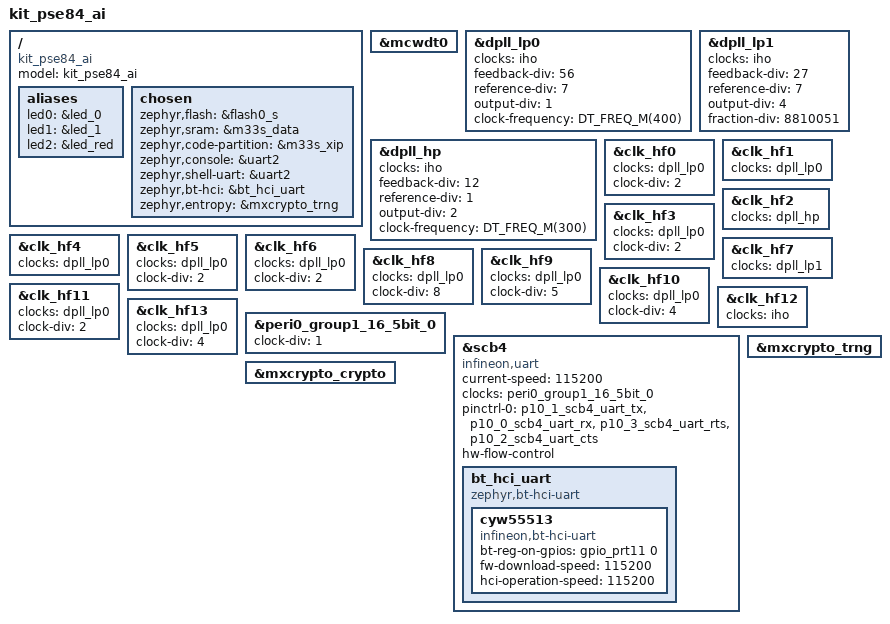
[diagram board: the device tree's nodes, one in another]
/*
 * SPDX-FileCopyrightText: Copyright (c) 2026 Infineon Technologies AG,
 * SPDX-FileCopyrightText: or an affiliate of Infineon Technologies AG. All rights reserved.
 *
 * SPDX-License-Identifier: Apache-2.0
 */

/dts-v1/;
#include <infineon/edge/mpns/pse846gps2dbzc4a_s.dtsi>
#include <infineon/edge/pse84/pse84.cm33.dtsi>
#include <infineon/edge/pse84/system_clocks.dtsi>

#include "kit_pse84_ai_common.dtsi"
#include "kit_pse84_ai_memory_map.dtsi"

/ {
	compatible = "kit_pse84_ai";
	model = "kit_pse84_ai";

	aliases {
		led0 = &led_0;
		led1 = &led_1;
		led2 = &led_red;
	};

	chosen {
		zephyr,flash = &flash0_s;
		zephyr,sram = &m33s_data;
		zephyr,code-partition = &m33s_xip;
		zephyr,console = &uart2;
		zephyr,shell-uart = &uart2;
		zephyr,bt-hci = &bt_hci_uart;
		zephyr,entropy = &mxcrypto_trng;
	};
};

&mcwdt0 {
	status = "okay";
};

&dpll_lp0 {
	clocks = <&iho>;
	feedback-div = <56>;
	reference-div = <7>;
	output-div = <1>;
	clock-frequency = <DT_FREQ_M(400)>;
	status = "okay";
};

&dpll_lp1 {
	clocks = <&iho>;
	feedback-div = <27>;
	reference-div = <7>;
	output-div = <4>;
	fraction-div = <8810051>;
	status = "okay";
};

&dpll_hp {
	clocks = <&iho>;
	feedback-div = <12>;
	reference-div = <1>;
	output-div = <2>;
	clock-frequency = <DT_FREQ_M(300)>;
	status = "okay";
};

&clk_hf0 {
	clocks = <&dpll_lp0>;
	clock-div = <2>;
	status = "okay";
};

&clk_hf1 {
	clocks = <&dpll_lp0>;
	status = "okay";
};

&clk_hf2 {
	clocks = <&dpll_hp>;
	status = "okay";
};

&clk_hf3 {
	clocks = <&dpll_lp0>;
	clock-div = <2>;
	status = "okay";
};

&clk_hf4 {
	clocks = <&dpll_lp0>;
	status = "okay";
};

&clk_hf5 {
	clocks = <&dpll_lp0>;
	clock-div = <2>;
	status = "okay";
};

&clk_hf6 {
	clocks = <&dpll_lp0>;
	clock-div = <2>;
	status = "okay";
};

&clk_hf7 {
	clocks = <&dpll_lp1>;
	status = "okay";
};

&clk_hf8 {
	clocks = <&dpll_lp0>;
	clock-div = <8>;
	status = "okay";
};

&clk_hf9 {
	clocks = <&dpll_lp0>;
	clock-div = <5>;
	status = "okay";
};

&clk_hf10 {
	clocks = <&dpll_lp0>;
	clock-div = <4>;
	status = "okay";
};

&clk_hf11 {
	clocks = <&dpll_lp0>;
	clock-div = <2>;
	status = "okay";
};

&clk_hf12 {
	clocks = <&iho>;
	status = "okay";
};

&clk_hf13 {
	clocks = <&dpll_lp0>;
	clock-div = <4>;
	status = "okay";
};

&peri0_group1_16_5bit_0 {
	clock-div = <1>;
	status = "okay";
};

uart4: &scb4 {
	compatible = "infineon,uart";

	current-speed = <115200>;

	clocks = <&peri0_group1_16_5bit_0>;

	/* HCI-UART pins */
	pinctrl-0 = <&p10_1_scb4_uart_tx &p10_0_scb4_uart_rx &p10_3_scb4_uart_rts
		     &p10_2_scb4_uart_cts>;
	pinctrl-names = "default";

	/* HW Flow control must be enabled for HCI H4 */
	hw-flow-control;
	status = "okay";

	bt_hci_uart: bt_hci_uart {
		compatible = "zephyr,bt-hci-uart";

		cyw55513 {
			compatible = "infineon,bt-hci-uart";
			bt-reg-on-gpios = <&gpio_prt11 0 GPIO_ACTIVE_HIGH>;
			fw-download-speed = <115200>;
			hci-operation-speed = <115200>;
			status = "okay";
		};
	};
};

&mxcrypto_trng {
	status = "okay";
};

&mxcrypto_crypto {
	status = "okay";
};
